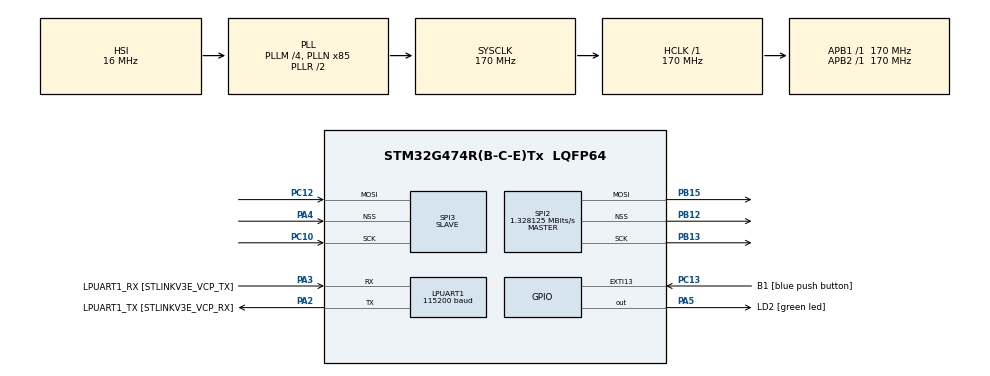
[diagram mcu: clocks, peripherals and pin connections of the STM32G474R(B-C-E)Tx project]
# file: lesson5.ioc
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LPUART1.BaudRate=115200
LPUART1.WordLength=UART_WORDLENGTH_8B
Mcu.Family=STM32G4
Mcu.Name=STM32G474R(B-C-E)Tx
Mcu.Package=LQFP64
NVIC.EXTI15_10_IRQn=true\:0\:0\:false\:false\:true\:true\:true
NVIC.PriorityGroup=NVIC_PRIORITYGROUP_4
NVIC.SPI3_IRQn=true\:0\:0\:false\:false\:true\:true\:true
PA13.GPIO_Label=T_SWDIO
PA13.Mode=Serial_Wire
PA13.Signal=SYS_JTMS-SWDIO
PA14.GPIO_Label=T_SWCLK
PA14.Mode=Serial_Wire
PA14.Signal=SYS_JTCK-SWCLK
PA2.GPIO_Label=LPUART1_TX [STLINKV3E_VCP_RX]
PA2.Mode=Asynchronous
PA2.Signal=LPUART1_TX
PA3.GPIO_Label=LPUART1_RX [STLINKV3E_VCP_TX]
PA3.Mode=Asynchronous
PA3.Signal=LPUART1_RX
PA4.Mode=NSS_Signal_Hard_Input
PA4.Signal=SPI3_NSS
PA5.GPIO_Label=LD2 [green led]
PA5.Signal=GPIO_Output
PB12.Mode=NSS_Signal_Hard_Output
PB12.Signal=SPI2_NSS
PB13.Mode=TX_Only_Simplex_Unidirect_Master
PB13.Signal=SPI2_SCK
PB15.Mode=TX_Only_Simplex_Unidirect_Master
PB15.Signal=SPI2_MOSI
PB3.GPIO_Label=T_SWO
PB3.Signal=SYS_JTDO-SWO
PC10.Mode=RX_Only_Simplex_Unidirect_Slave
PC10.Signal=SPI3_SCK
PC12.Mode=RX_Only_Simplex_Unidirect_Slave
PC12.Signal=SPI3_MOSI
PC13.GPIO_Label=B1 [blue push button]
PC13.Signal=GPXTI13
PC14-OSC32_IN.Mode=LSE-External-Oscillator
PC14-OSC32_IN.Signal=RCC_OSC32_IN
PC15-OSC32_OUT.Mode=LSE-External-Oscillator
PC15-OSC32_OUT.Signal=RCC_OSC32_OUT
PF0-OSC_IN.Mode=HSE-External-Oscillator
PF0-OSC_IN.Signal=RCC_OSC_IN
PF1-OSC_OUT.Mode=HSE-External-Oscillator
PF1-OSC_OUT.Signal=RCC_OSC_OUT
ProjectManager.HeapSize=0x200
ProjectManager.StackSize=0x400
ProjectManager.TargetToolchain=STM32CubeIDE
RCC.ADC12Freq_Value=170000000
RCC.ADC345Freq_Value=170000000
RCC.AHBFreq_Value=170000000
RCC.APB1Freq_Value=170000000
RCC.APB1TimFreq_Value=170000000
RCC.APB2Freq_Value=170000000
RCC.APB2TimFreq_Value=170000000
RCC.CortexFreq_Value=170000000
RCC.EXTERNAL_CLOCK_VALUE=12288000
RCC.HCLKFreq_Value=170000000
RCC.HSE_VALUE=24000000
RCC.HSI48_VALUE=48000000
RCC.HSI_VALUE=16000000
RCC.PLLM=RCC_PLLM_DIV4
RCC.PLLN=85
RCC.RTCClockSelection=RCC_RTCCLKSOURCE_LSE
RCC.SYSCLKFreq_VALUE=170000000
RCC.SYSCLKSource=RCC_SYSCLKSOURCE_PLLCLK
RCC.USBFreq_Value=170000000
RCC.VCOOutputFreq_Value=340000000
SPI2.BaudRatePrescaler=SPI_BAUDRATEPRESCALER_128
SPI2.CalculateBaudRate=1.328125 MBits/s
SPI2.DataSize=SPI_DATASIZE_8BIT
SPI2.Direction=SPI_DIRECTION_2LINES
SPI2.Mode=SPI_MODE_MASTER
SPI2.VirtualNSS=VM_NSSHARD
SPI2.VirtualType=VM_MASTER
SPI3.DataSize=SPI_DATASIZE_8BIT
SPI3.Direction=SPI_DIRECTION_2LINES_RXONLY
SPI3.Mode=SPI_MODE_SLAVE
SPI3.VirtualNSS=VM_NSSHARD
SPI3.VirtualType=VM_SLAVE
VP_SYS_VS_DBSignals.Mode=DisableDeadBatterySignals
board=NUCLEO-G474RE

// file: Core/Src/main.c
/* USER CODE BEGIN Header */
/**
  ******************************************************************************
  * @file           : main.c
  * @brief          : Main program body
  ******************************************************************************
  * @attention
  *
  * Copyright (c) 2022 STMicroelectronics.
  * All rights reserved.
  *
  * This software is licensed under terms that can be found in the LICENSE file
  * in the root directory of this software component.
  * If no LICENSE file comes with this software, it is provided AS-IS.
  *
  ******************************************************************************
  */
/* USER CODE END Header */
#include "main.h"

UART_HandleTypeDef hlpuart1;

SPI_HandleTypeDef hspi2;
SPI_HandleTypeDef hspi3;

/* USER CODE BEGIN PV */
uint8_t buffTX[1]={0};
uint8_t buffRX[1]={0};
/* USER CODE END PV */

void SystemClock_Config(void);
static void MX_GPIO_Init(void);
static void MX_LPUART1_UART_Init(void);
static void MX_SPI2_Init(void);
static void MX_SPI3_Init(void);

int main(void)
{

  /* MCU Configuration--------------------------------------------------------*/

  /* Reset of all peripherals, Initializes the Flash interface and the Systick. */
  HAL_Init();

  /* Configure the system clock */
  SystemClock_Config();

  /* Initialize all configured peripherals */
  MX_GPIO_Init();
  MX_LPUART1_UART_Init();
  MX_SPI2_Init();
  MX_SPI3_Init();
  /* USER CODE BEGIN 2 */

  HAL_SPI_Receive_IT(&hspi3, buffRX, 1);
  /* USER CODE END 2 */

  /* Infinite loop */
  while (1)
  {

    /* USER CODE BEGIN 3 */
      //buffTX[0] = 0b10101010;

      // HAL_SPI_Transmit(&hspi2, buffTX, 1, HAL_MAX_DELAY);
       HAL_Delay(100);
  }
  /* USER CODE END 3 */
}

void SystemClock_Config(void)
{
  RCC_OscInitTypeDef RCC_OscInitStruct = {0};
  RCC_ClkInitTypeDef RCC_ClkInitStruct = {0};

  /** Configure the main internal regulator output voltage
  */
  HAL_PWREx_ControlVoltageScaling(PWR_REGULATOR_VOLTAGE_SCALE1_BOOST);
  /** Initializes the RCC Oscillators according to the specified parameters
  * in the RCC_OscInitTypeDef structure.
  */
  RCC_OscInitStruct.OscillatorType = RCC_OSCILLATORTYPE_HSI;
  RCC_OscInitStruct.HSIState = RCC_HSI_ON;
  RCC_OscInitStruct.HSICalibrationValue = RCC_HSICALIBRATION_DEFAULT;
  RCC_OscInitStruct.PLL.PLLState = RCC_PLL_ON;
  RCC_OscInitStruct.PLL.PLLSource = RCC_PLLSOURCE_HSI;
  RCC_OscInitStruct.PLL.PLLM = RCC_PLLM_DIV4;
  RCC_OscInitStruct.PLL.PLLN = 85;
  RCC_OscInitStruct.PLL.PLLP = RCC_PLLP_DIV2;
  RCC_OscInitStruct.PLL.PLLQ = RCC_PLLQ_DIV2;
  RCC_OscInitStruct.PLL.PLLR = RCC_PLLR_DIV2;
  if (HAL_RCC_OscConfig(&RCC_OscInitStruct) != HAL_OK)
  {
    Error_Handler();
  }
  /** Initializes the CPU, AHB and APB buses clocks
  */
  RCC_ClkInitStruct.ClockType = RCC_CLOCKTYPE_HCLK|RCC_CLOCKTYPE_SYSCLK
                              |RCC_CLOCKTYPE_PCLK1|RCC_CLOCKTYPE_PCLK2;
  RCC_ClkInitStruct.SYSCLKSource = RCC_SYSCLKSOURCE_PLLCLK;
  RCC_ClkInitStruct.AHBCLKDivider = RCC_SYSCLK_DIV1;
  RCC_ClkInitStruct.APB1CLKDivider = RCC_HCLK_DIV1;
  RCC_ClkInitStruct.APB2CLKDivider = RCC_HCLK_DIV1;

  if (HAL_RCC_ClockConfig(&RCC_ClkInitStruct, FLASH_LATENCY_4) != HAL_OK)
  {
    Error_Handler();
  }
}

static void MX_LPUART1_UART_Init(void)
{

  hlpuart1.Instance = LPUART1;
  hlpuart1.Init.BaudRate = 115200;
  hlpuart1.Init.WordLength = UART_WORDLENGTH_8B;
  hlpuart1.Init.StopBits = UART_STOPBITS_1;
  hlpuart1.Init.Parity = UART_PARITY_NONE;
  hlpuart1.Init.Mode = UART_MODE_TX_RX;
  hlpuart1.Init.HwFlowCtl = UART_HWCONTROL_NONE;
  hlpuart1.Init.OneBitSampling = UART_ONE_BIT_SAMPLE_DISABLE;
  hlpuart1.Init.ClockPrescaler = UART_PRESCALER_DIV1;
  hlpuart1.AdvancedInit.AdvFeatureInit = UART_ADVFEATURE_NO_INIT;
  if (HAL_UART_Init(&hlpuart1) != HAL_OK)
  {
    Error_Handler();
  }
  if (HAL_UARTEx_SetTxFifoThreshold(&hlpuart1, UART_TXFIFO_THRESHOLD_1_8) != HAL_OK)
  {
    Error_Handler();
  }
  if (HAL_UARTEx_SetRxFifoThreshold(&hlpuart1, UART_RXFIFO_THRESHOLD_1_8) != HAL_OK)
  {
    Error_Handler();
  }
  if (HAL_UARTEx_DisableFifoMode(&hlpuart1) != HAL_OK)
  {
    Error_Handler();
  }

}

static void MX_SPI2_Init(void)
{

  /* SPI2 parameter configuration*/
  hspi2.Instance = SPI2;
  hspi2.Init.Mode = SPI_MODE_MASTER;
  hspi2.Init.Direction = SPI_DIRECTION_2LINES;
  hspi2.Init.DataSize = SPI_DATASIZE_8BIT;
  hspi2.Init.CLKPolarity = SPI_POLARITY_LOW;
  hspi2.Init.CLKPhase = SPI_PHASE_1EDGE;
  hspi2.Init.NSS = SPI_NSS_HARD_OUTPUT;
  hspi2.Init.BaudRatePrescaler = SPI_BAUDRATEPRESCALER_128;
  hspi2.Init.FirstBit = SPI_FIRSTBIT_MSB;
  hspi2.Init.TIMode = SPI_TIMODE_DISABLE;
  hspi2.Init.CRCCalculation = SPI_CRCCALCULATION_DISABLE;
  hspi2.Init.CRCPolynomial = 7;
  hspi2.Init.CRCLength = SPI_CRC_LENGTH_DATASIZE;
  hspi2.Init.NSSPMode = SPI_NSS_PULSE_ENABLE;
  if (HAL_SPI_Init(&hspi2) != HAL_OK)
  {
    Error_Handler();
  }

}

static void MX_SPI3_Init(void)
{

  /* SPI3 parameter configuration*/
  hspi3.Instance = SPI3;
  hspi3.Init.Mode = SPI_MODE_SLAVE;
  hspi3.Init.Direction = SPI_DIRECTION_2LINES_RXONLY;
  hspi3.Init.DataSize = SPI_DATASIZE_8BIT;
  hspi3.Init.CLKPolarity = SPI_POLARITY_LOW;
  hspi3.Init.CLKPhase = SPI_PHASE_1EDGE;
  hspi3.Init.NSS = SPI_NSS_HARD_INPUT;
  hspi3.Init.FirstBit = SPI_FIRSTBIT_MSB;
  hspi3.Init.TIMode = SPI_TIMODE_DISABLE;
  hspi3.Init.CRCCalculation = SPI_CRCCALCULATION_DISABLE;
  hspi3.Init.CRCPolynomial = 7;
  hspi3.Init.CRCLength = SPI_CRC_LENGTH_DATASIZE;
  hspi3.Init.NSSPMode = SPI_NSS_PULSE_DISABLE;
  if (HAL_SPI_Init(&hspi3) != HAL_OK)
  {
    Error_Handler();
  }

}

static void MX_GPIO_Init(void)
{
  GPIO_InitTypeDef GPIO_InitStruct = {0};

  /* GPIO Ports Clock Enable */
  __HAL_RCC_GPIOC_CLK_ENABLE();
  __HAL_RCC_GPIOF_CLK_ENABLE();
  __HAL_RCC_GPIOA_CLK_ENABLE();
  __HAL_RCC_GPIOB_CLK_ENABLE();

  /*Configure GPIO pin Output Level */
  HAL_GPIO_WritePin(LD2_GPIO_Port, LD2_Pin, GPIO_PIN_RESET);

  /*Configure GPIO pin : B1_Pin */
  GPIO_InitStruct.Pin = B1_Pin;
  GPIO_InitStruct.Mode = GPIO_MODE_IT_RISING;
  GPIO_InitStruct.Pull = GPIO_NOPULL;
  HAL_GPIO_Init(B1_GPIO_Port, &GPIO_InitStruct);

  /*Configure GPIO pin : LD2_Pin */
  GPIO_InitStruct.Pin = LD2_Pin;
  GPIO_InitStruct.Mode = GPIO_MODE_OUTPUT_PP;
  GPIO_InitStruct.Pull = GPIO_NOPULL;
  GPIO_InitStruct.Speed = GPIO_SPEED_FREQ_LOW;
  HAL_GPIO_Init(LD2_GPIO_Port, &GPIO_InitStruct);

  /* EXTI interrupt init*/
  HAL_NVIC_SetPriority(EXTI15_10_IRQn, 0, 0);
  HAL_NVIC_EnableIRQ(EXTI15_10_IRQn);

}

/* USER CODE BEGIN 4 */

void HAL_SPI_RxCpltCallback(SPI_HandleTypeDef * hspi)
{
	if (hspi==&hspi3){
		HAL_GPIO_TogglePin(LD2_GPIO_Port, LD2_Pin);
		HAL_SPI_Receive_IT(&hspi3, buffRX, 1);
	}
}
/* USER CODE END 4 */

void Error_Handler(void)
{
  __disable_irq();
  while (1)
  {
  }
}
